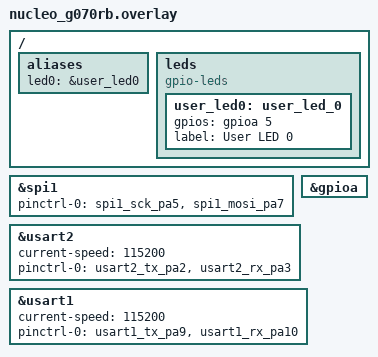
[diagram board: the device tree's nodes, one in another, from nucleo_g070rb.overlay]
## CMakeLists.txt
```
cmake_minimum_required(VERSION 3.20.0)
find_package(Zephyr REQUIRED HINTS $ENV{ZEPHYR_BASE})
project(rtos_project)

# Add component directories to include path
target_include_directories(app PRIVATE 
    src
    src/led_driver 
    src/wifi_bridge
)

# List sources
target_sources(app PRIVATE
    src/main.c
    src/led_driver/led_driver.c
    src/wifi_bridge/wifi_bridge.c
    
    # Examples
    src/examples/ex_blinky.c
    src/examples/ex_math.c
    # src/examples/ex_sem.c
)
```

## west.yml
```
manifest:
  version: 0.13

  defaults:
    remote: zephyrproject

  remotes:
    - name: zephyrproject
      url-base: https://github.com/zephyrproject-rtos

  projects:
    - name: zephyr
      path: zephyr
      revision: main
```

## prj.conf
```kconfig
# ==============================================================================
# Zephyr RTOS Configuration for STM32 Nucleo-G070RB
# ==============================================================================

# ------------------------------------------------------------------------------
# System and Memory Configuration
# ------------------------------------------------------------------------------
CONFIG_MAIN_STACK_SIZE=2048

# System timing - 1ms tick resolution for k_msleep()
CONFIG_SYS_CLOCK_TICKS_PER_SEC=1000

# ------------------------------------------------------------------------------
# Console and UART
# ------------------------------------------------------------------------------
CONFIG_CONSOLE=y
CONFIG_UART_CONSOLE=y
CONFIG_STDOUT_CONSOLE=y
CONFIG_PRINTK=y

# ------------------------------------------------------------------------------
# Logging System
# ------------------------------------------------------------------------------
# Levels: 0=OFF, 1=ERR, 2=WRN, 3=INF, 4=DBG
CONFIG_LOG=y
CONFIG_LOG_DEFAULT_LEVEL=3

# ------------------------------------------------------------------------------
# Debug Settings (disable in production for smaller code size)
# ------------------------------------------------------------------------------
CONFIG_ASSERT=y
CONFIG_DEBUG=y

# ------------------------------------------------------------------------------
# GPIO Support
# ------------------------------------------------------------------------------
CONFIG_GPIO=y

# ------------------------------------------------------------------------------
# SPI Driver Configuration
# ------------------------------------------------------------------------------
CONFIG_SPI=y
CONFIG_SPI_STM32=y
CONFIG_SPI_INIT_PRIORITY=80

# ------------------------------------------------------------------------------
# Pin Control and Clocks (required for STM32)
# ------------------------------------------------------------------------------
CONFIG_PINCTRL=y
CONFIG_CLOCK_CONTROL=y

# ------------------------------------------------------------------------------
# Interactive Shell via Serial
# ------------------------------------------------------------------------------
CONFIG_SHELL=y
CONFIG_SHELL_BACKEND_SERIAL=y

# ------------------------------------------------------------------------------
# Thread Configuration
# ------------------------------------------------------------------------------
CONFIG_THREAD_NAME=y

# ------------------------------------------------------------------------------
# SPI Support
# ------------------------------------------------------------------------------
CONFIG_SPI=y

# ------------------------------------------------------------------------------
# UART Support for Wi-Fi Bridge
# ------------------------------------------------------------------------------
CONFIG_SERIAL=y
CONFIG_UART_INTERRUPT_DRIVEN=y

# ------------------------------------------------------------------------------
# Optional: Uncomment for newlib/nano C library support
# ------------------------------------------------------------------------------
#CONFIG_NEWLIB_LIBC=y
```

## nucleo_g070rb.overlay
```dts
#include <zephyr/dt-bindings/led/led.h>

/ {
    /* Define the aliases and the physical LED node for the Blinky example */
    aliases {
        led0 = &user_led0;
    };

    leds {
        compatible = "gpio-leds";
        user_led0: user_led_0 {
            // Note: This pin definition must be correct for your board
            gpios = <&gpioa 5 GPIO_ACTIVE_HIGH>; 
            label = "User LED 0";
            status = "okay";
        };
    };
};

/* Enable SPI1 for manual WS2812 control */
&spi1 {
    status = "okay";
    pinctrl-0 = <&spi1_sck_pa5 &spi1_mosi_pa7>;
    pinctrl-names = "default";
};

/* Ensure GPIO Port A is enabled (pins PA5 and PA7 are on this port) */
&gpioa {
    status = "okay";
};

/* Enable USART2 for Console/Shell (USB) */
&usart2 {
    status = "okay";
    current-speed = <115200>;
    pinctrl-0 = <&usart2_tx_pa2 &usart2_rx_pa3>;
    pinctrl-names = "default";
};

/* Enable USART1 for Wi-Fi Bridge (Pico connection) */
/* PA9 = D8 (TX), PA10 = D2 (RX) */
&usart1 {
    status = "okay";
    current-speed = <115200>;
    pinctrl-0 = <&usart1_tx_pa9 &usart1_rx_pa10>;
    pinctrl-names = "default";
};
```

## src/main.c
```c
#include "examples/ex_blinky.h"
#include "examples/ex_math.h"
#include "examples/ex_sem.h"
#include "wifi_bridge/wifi_bridge.h"

int main(void)
{

    // run_blinky();
    // run_math();
    // run_rgb();
    run_wifi_bridge();

    // ex_sem_start();

    return 0;
}
```
